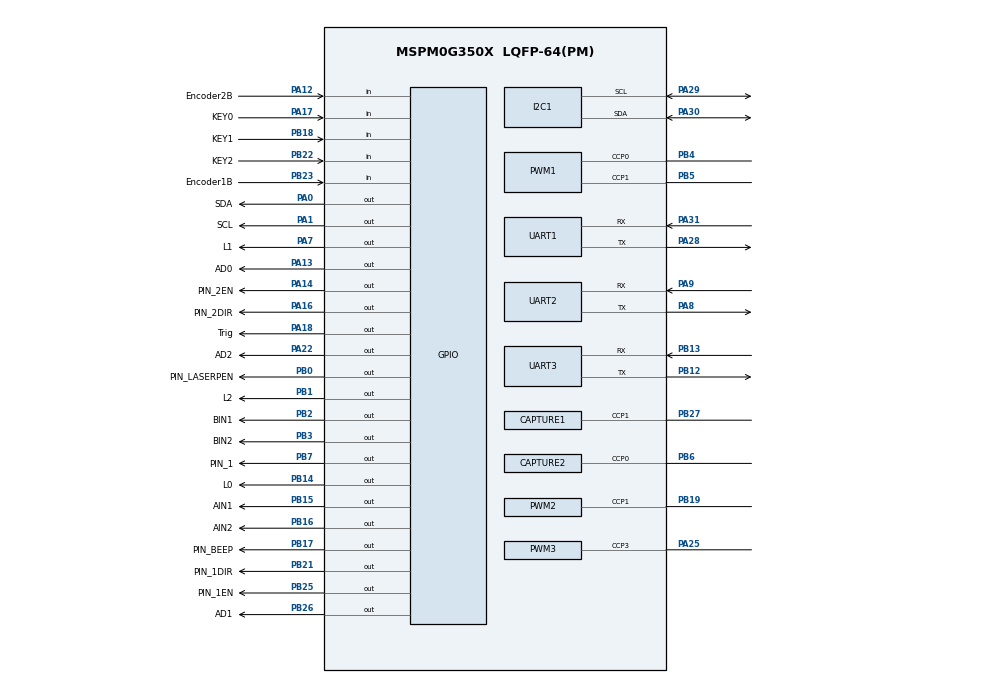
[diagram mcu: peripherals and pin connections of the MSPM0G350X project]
/**
 * @cliArgs --device "MSPM0G350X" --part "Default" --package "LQFP-64(PM)" --product "mspm0_sdk@2.05.01.01"
 * @versions {"tool":"1.24.0+4110"}
 */

/**
 * Import the modules used in this configuration.
 */
const ADC12    = scripting.addModule("/ti/driverlib/ADC12", {}, false);
const ADC121   = ADC12.addInstance();
const Board    = scripting.addModule("/ti/driverlib/Board");
const CAPTURE  = scripting.addModule("/ti/driverlib/CAPTURE", {}, false);
const CAPTURE1 = CAPTURE.addInstance();
const CAPTURE2 = CAPTURE.addInstance();
const DMA      = scripting.addModule("/ti/driverlib/DMA");
const GPIO     = scripting.addModule("/ti/driverlib/GPIO", {}, false);
const GPIO1    = GPIO.addInstance();
const GPIO2    = GPIO.addInstance();
const GPIO3    = GPIO.addInstance();
const GPIO4    = GPIO.addInstance();
const GPIO5    = GPIO.addInstance();
const GPIO6    = GPIO.addInstance();
const GPIO7    = GPIO.addInstance();
const GPIO8    = GPIO.addInstance();
const GPIO9    = GPIO.addInstance();
const GPIO10   = GPIO.addInstance();
const I2C      = scripting.addModule("/ti/driverlib/I2C", {}, false);
const I2C1     = I2C.addInstance();
const PWM      = scripting.addModule("/ti/driverlib/PWM", {}, false);
const PWM1     = PWM.addInstance();
const PWM2     = PWM.addInstance();
const PWM3     = PWM.addInstance();
const SYSCTL   = scripting.addModule("/ti/driverlib/SYSCTL");
const TIMER    = scripting.addModule("/ti/driverlib/TIMER", {}, false);
const TIMER1   = TIMER.addInstance();
const UART     = scripting.addModule("/ti/driverlib/UART", {}, false);
const UART1    = UART.addInstance();
const UART2    = UART.addInstance();
const UART3    = UART.addInstance();

/**
 * Write custom configuration values to the imported modules.
 */
ADC121.repeatMode                        = true;
ADC121.$name                             = "ADC_CHASE";
ADC121.adcMem5chansel                    = "DL_ADC12_INPUT_CHAN_5";
ADC121.powerDownMode                     = "DL_ADC12_POWER_DOWN_MODE_MANUAL";
ADC121.configureDMA                      = true;
ADC121.enabledDMATriggers                = ["DL_ADC12_DMA_MEM0_RESULT_LOADED"];
ADC121.sampCnt                           = 1;
ADC121.adcMem0chansel                    = "DL_ADC12_INPUT_CHAN_5";
ADC121.sampleTime0                       = "62.5us";
ADC121.enabledInterrupts                 = ["DL_ADC12_INTERRUPT_DMA_DONE"];
ADC121.interruptPriority                 = "1";
ADC121.sampClkDiv                        = "DL_ADC12_CLOCK_DIVIDE_8";
ADC121.DMA_CHANNEL.$name                 = "DMA_CH0";
ADC121.DMA_CHANNEL.addressMode           = "f2b";
ADC121.DMA_CHANNEL.srcLength             = "HALF_WORD";
ADC121.DMA_CHANNEL.dstLength             = "HALF_WORD";
ADC121.DMA_CHANNEL.configureTransferSize = true;
ADC121.DMA_CHANNEL.transferMode          = "FULL_CH_REPEAT_SINGLE";
ADC121.DMA_CHANNEL.transferSize          = 20;
ADC121.DMA_CHANNEL.peripheral.$assign    = "DMA_CH1";
ADC121.adcPin5Config.$name               = "ti_driverlib_gpio_GPIOPinGeneric5";

Board.genPeriphPinFile = true;
Board.genFileMod.$name = "ti_driverlib_BoardPins0";

CAPTURE1.$name                      = "Encoder1A";
CAPTURE1.timerPeriod                = "1ms";
CAPTURE1.ccIndex                    = 1;
CAPTURE1.interrupts                 = ["CC1_DN"];
CAPTURE1.peripheral.$assign         = "TIMG6";
CAPTURE1.peripheral.ccp1Pin.$assign = "PB27";
CAPTURE1.ccp1PinConfig.$name        = "ti_driverlib_gpio_GPIOPinGeneric1";

CAPTURE2.$name                              = "Encoder2A";
CAPTURE2.timerPeriod                        = "1 ms";
CAPTURE2.interrupts                         = ["CC0_DN"];
CAPTURE2.peripheral.$assign                 = "TIMG8";
CAPTURE2.peripheral.ccp0Pin.$assign         = "PB6";
CAPTURE2.ccp0PinConfig.hideOutputInversion  = scripting.forceWrite(false);
CAPTURE2.ccp0PinConfig.onlyInternalResistor = scripting.forceWrite(false);
CAPTURE2.ccp0PinConfig.passedPeripheralType = scripting.forceWrite("Digital");
CAPTURE2.ccp0PinConfig.$name                = "ti_driverlib_gpio_GPIOPinGeneric8";

GPIO1.$name                         = "MOTOR_IN";
GPIO1.associatedPins.create(4);
GPIO1.associatedPins[0].$name       = "AIN1";
GPIO1.associatedPins[0].pin.$assign = "PB15";
GPIO1.associatedPins[1].$name       = "AIN2";
GPIO1.associatedPins[1].pin.$assign = "PB16";
GPIO1.associatedPins[2].$name       = "BIN1";
GPIO1.associatedPins[2].pin.$assign = "PB2";
GPIO1.associatedPins[3].$name       = "BIN2";
GPIO1.associatedPins[3].pin.$assign = "PB3";

GPIO2.$name                         = "GPIO_Encoder";
GPIO2.associatedPins.create(2);
GPIO2.associatedPins[0].$name       = "Encoder1B";
GPIO2.associatedPins[0].direction   = "INPUT";
GPIO2.associatedPins[0].pin.$assign = "PB23";
GPIO2.associatedPins[1].$name       = "Encoder2B";
GPIO2.associatedPins[1].direction   = "INPUT";
GPIO2.associatedPins[1].pin.$assign = "PA12";

GPIO3.$name                         = "GPIO_STBY";
GPIO3.associatedPins[0].$name       = "PIN_1";
GPIO3.associatedPins[0].pin.$assign = "PB7";

GPIO4.$name                              = "GPIO_TRACE";
GPIO4.associatedPins.create(3);
GPIO4.associatedPins[0].internalResistor = "PULL_UP";
GPIO4.associatedPins[0].$name            = "AD0";
GPIO4.associatedPins[0].pin.$assign      = "PA13";
GPIO4.associatedPins[1].internalResistor = "PULL_UP";
GPIO4.associatedPins[1].$name            = "AD1";
GPIO4.associatedPins[1].pin.$assign      = "PB26";
GPIO4.associatedPins[2].internalResistor = "PULL_UP";
GPIO4.associatedPins[2].$name            = "AD2";
GPIO4.associatedPins[2].pin.$assign      = "PA22";

GPIO5.$name                              = "KEY";
GPIO5.associatedPins.create(3);
GPIO5.associatedPins[0].direction        = "INPUT";
GPIO5.associatedPins[0].polarity         = "FALL";
GPIO5.associatedPins[0].$name            = "KEY0";
GPIO5.associatedPins[0].internalResistor = "PULL_DOWN";
GPIO5.associatedPins[0].pin.$assign      = "PA17";
GPIO5.associatedPins[1].direction        = "INPUT";
GPIO5.associatedPins[1].polarity         = "FALL";
GPIO5.associatedPins[1].$name            = "KEY1";
GPIO5.associatedPins[1].internalResistor = "PULL_DOWN";
GPIO5.associatedPins[1].pin.$assign      = "PB18";
GPIO5.associatedPins[2].direction        = "INPUT";
GPIO5.associatedPins[2].polarity         = "FALL";
GPIO5.associatedPins[2].$name            = "KEY2";
GPIO5.associatedPins[2].internalResistor = "PULL_DOWN";
GPIO5.associatedPins[2].pin.$assign      = "PB22";

GPIO6.$name                              = "LED";
GPIO6.associatedPins.create(3);
GPIO6.associatedPins[0].$name            = "L0";
GPIO6.associatedPins[0].initialValue     = "SET";
GPIO6.associatedPins[0].internalResistor = "PULL_UP";
GPIO6.associatedPins[0].pin.$assign      = "PB14";
GPIO6.associatedPins[1].initialValue     = "SET";
GPIO6.associatedPins[1].$name            = "L1";
GPIO6.associatedPins[1].internalResistor = "PULL_UP";
GPIO6.associatedPins[1].pin.$assign      = "PA7";
GPIO6.associatedPins[2].initialValue     = "SET";
GPIO6.associatedPins[2].$name            = "L2";
GPIO6.associatedPins[2].internalResistor = "PULL_UP";
GPIO6.associatedPins[2].pin.$assign      = "PB1";

GPIO7.$name                         = "GPIO_OLED";
GPIO7.associatedPins.create(2);
GPIO7.associatedPins[0].$name       = "SCL";
GPIO7.associatedPins[0].pin.$assign = "PA1";
GPIO7.associatedPins[1].$name       = "SDA";
GPIO7.associatedPins[1].pin.$assign = "PA0";

GPIO8.$name                         = "GPIO_BUJIN";
GPIO8.associatedPins.create(4);
GPIO8.associatedPins[0].$name       = "PIN_1EN";
GPIO8.associatedPins[0].pin.$assign = "PB25";
GPIO8.associatedPins[1].$name       = "PIN_1DIR";
GPIO8.associatedPins[1].pin.$assign = "PB21";
GPIO8.associatedPins[2].$name       = "PIN_2EN";
GPIO8.associatedPins[2].pin.$assign = "PA14";
GPIO8.associatedPins[3].$name       = "PIN_2DIR";
GPIO8.associatedPins[3].pin.$assign = "PA16";

GPIO9.$name                              = "SR04";
GPIO9.associatedPins.create(2);
GPIO9.associatedPins[0].$name            = "Trig";
GPIO9.associatedPins[0].initialValue     = "SET";
GPIO9.associatedPins[0].pin.$assign      = "PA18";
GPIO9.associatedPins[1].direction        = "INPUT";
GPIO9.associatedPins[1].polarity         = "RISE_FALL";
GPIO9.associatedPins[1].internalResistor = "PULL_DOWN";
GPIO9.associatedPins[1].$name            = "Echo";
GPIO9.associatedPins[1].interruptEn      = true;

GPIO10.$name                              = "GPIO_ADD";
GPIO10.associatedPins.create(2);
GPIO10.associatedPins[0].$name            = "PIN_BEEP";
GPIO10.associatedPins[0].internalResistor = "PULL_UP";
GPIO10.associatedPins[0].pin.$assign      = "PB17";
GPIO10.associatedPins[1].$name            = "PIN_LASERPEN";
GPIO10.associatedPins[1].pin.$assign      = "PB0";

I2C1.$name                             = "I2C_1";
I2C1.peripheral.$assign                = "I2C1";
I2C1.peripheral.sdaPin.$assign         = "PA30";
I2C1.peripheral.sclPin.$assign         = "PA29";
I2C1.sdaPinConfig.hideOutputInversion  = scripting.forceWrite(false);
I2C1.sdaPinConfig.onlyInternalResistor = scripting.forceWrite(false);
I2C1.sdaPinConfig.passedPeripheralType = scripting.forceWrite("Digital");
I2C1.sdaPinConfig.$name                = "ti_driverlib_gpio_GPIOPinGeneric16";
I2C1.sclPinConfig.hideOutputInversion  = scripting.forceWrite(false);
I2C1.sclPinConfig.onlyInternalResistor = scripting.forceWrite(false);
I2C1.sclPinConfig.passedPeripheralType = scripting.forceWrite("Digital");
I2C1.sclPinConfig.$name                = "ti_driverlib_gpio_GPIOPinGeneric17";

PWM1.$name                              = "Motor";
PWM1.clockPrescale                      = 32;
PWM1.pwmMode                            = "EDGE_ALIGN_UP";
PWM1.timerCount                         = 100;
PWM1.peripheral.$assign                 = "TIMA1";
PWM1.peripheral.ccp0Pin.$assign         = "PB4";
PWM1.peripheral.ccp1Pin.$assign         = "PB5";
PWM1.PWM_CHANNEL_0.$name                = "ti_driverlib_pwm_PWMTimerCC2";
PWM1.PWM_CHANNEL_1.$name                = "ti_driverlib_pwm_PWMTimerCC3";
PWM1.ccp0PinConfig.direction            = scripting.forceWrite("OUTPUT");
PWM1.ccp0PinConfig.hideOutputInversion  = scripting.forceWrite(false);
PWM1.ccp0PinConfig.onlyInternalResistor = scripting.forceWrite(false);
PWM1.ccp0PinConfig.passedPeripheralType = scripting.forceWrite("Digital");
PWM1.ccp0PinConfig.$name                = "ti_driverlib_gpio_GPIOPinGeneric6";
PWM1.ccp1PinConfig.direction            = scripting.forceWrite("OUTPUT");
PWM1.ccp1PinConfig.hideOutputInversion  = scripting.forceWrite(false);
PWM1.ccp1PinConfig.onlyInternalResistor = scripting.forceWrite(false);
PWM1.ccp1PinConfig.passedPeripheralType = scripting.forceWrite("Digital");
PWM1.ccp1PinConfig.$name                = "ti_driverlib_gpio_GPIOPinGeneric7";

PWM2.ccIndex                            = [1];
PWM2.$name                              = "PWM_BUJIN_X";
PWM2.interrupts                         = ["ZERO_EVENT"];
PWM2.interruptPriority                  = "1";
PWM2.clockPrescale                      = 64;
PWM2.ccp1PinConfig.direction            = scripting.forceWrite("OUTPUT");
PWM2.ccp1PinConfig.hideOutputInversion  = scripting.forceWrite(false);
PWM2.ccp1PinConfig.onlyInternalResistor = scripting.forceWrite(false);
PWM2.ccp1PinConfig.passedPeripheralType = scripting.forceWrite("Digital");
PWM2.ccp1PinConfig.$name                = "ti_driverlib_gpio_GPIOPinGeneric13";
PWM2.peripheral.$assign                 = "TIMG7";
PWM2.peripheral.ccp1Pin.$assign         = "PB19";
PWM2.PWM_CHANNEL_1.$name                = "ti_driverlib_pwm_PWMTimerCC4";

PWM3.$name                      = "PWM_BUJIN_Y";
PWM3.ccIndex                    = [3];
PWM3.interrupts                 = ["ZERO_EVENT"];
PWM3.interruptPriority          = "1";
PWM3.clockPrescale              = 64;
PWM3.peripheral.ccp3Pin.$assign = "PA25";
PWM3.PWM_CHANNEL_3.$name        = "ti_driverlib_pwm_PWMTimerCC0";
PWM3.ccp3PinConfig.$name        = "ti_driverlib_gpio_GPIOPinGeneric4";

SYSCTL.forceDefaultClkConfig = true;

TIMER1.timerClkPrescale   = 32;
TIMER1.interrupts         = ["ZERO"];
TIMER1.timerMode          = "PERIODIC";
TIMER1.$name              = "motor_CLOCK";
TIMER1.timerPeriod        = "10 ms";
TIMER1.interruptPriority  = "1";
TIMER1.peripheral.$assign = "TIMG0";

UART1.$name                             = "UART_0";
UART1.targetBaudRate                    = 115200;
UART1.enableFIFO                        = true;
UART1.rxFifoThreshold                   = "DL_UART_RX_FIFO_LEVEL_3_4_FULL";
UART1.enabledDMARXTriggers              = "DL_UART_DMA_INTERRUPT_RX";
UART1.enabledInterrupts                 = ["DMA_DONE_RX","RX_TIMEOUT_ERROR"];
UART1.peripheral.$assign                = "UART0";
UART1.peripheral.rxPin.$assign          = "PA31";
UART1.peripheral.txPin.$assign          = "PA28";
UART1.txPinConfig.$name                 = "ti_driverlib_gpio_GPIOPinGeneric2";
UART1.rxPinConfig.$name                 = "ti_driverlib_gpio_GPIOPinGeneric3";
UART1.DMA_CHANNEL_RX.addressMode        = "f2b";
UART1.DMA_CHANNEL_RX.srcLength          = "BYTE";
UART1.DMA_CHANNEL_RX.dstLength          = "BYTE";
UART1.DMA_CHANNEL_RX.transferMode       = "FULL_CH_REPEAT_SINGLE";
UART1.DMA_CHANNEL_RX.$name              = "DMA_MAXCI";
UART1.DMA_CHANNEL_RX.peripheral.$assign = "DMA_CH2";

UART2.$name                    = "UART_1";
UART2.enableFIFO               = true;
UART2.rxFifoThreshold          = "DL_UART_RX_FIFO_LEVEL_3_4_FULL";
UART2.enabledInterrupts        = ["RX"];
UART2.peripheral.$assign       = "UART1";
UART2.peripheral.rxPin.$assign = "PA9";
UART2.peripheral.txPin.$assign = "PA8";
UART2.txPinConfig.$name        = "ti_driverlib_gpio_GPIOPinGeneric10";
UART2.rxPinConfig.$name        = "ti_driverlib_gpio_GPIOPinGeneric11";

UART3.$name                             = "UART_3";
UART3.targetBaudRate                    = 230400;
UART3.rxFifoThreshold                   = "DL_UART_RX_FIFO_LEVEL_3_4_FULL";
UART3.enabledDMARXTriggers              = "DL_UART_DMA_INTERRUPT_RX";
UART3.enabledInterrupts                 = ["DMA_DONE_RX","RX_TIMEOUT_ERROR"];
UART3.enableFIFO                        = true;
UART3.peripheral.$assign                = "UART3";
UART3.peripheral.rxPin.$assign          = "PB13";
UART3.peripheral.txPin.$assign          = "PB12";
UART3.txPinConfig.direction             = scripting.forceWrite("OUTPUT");
UART3.txPinConfig.hideOutputInversion   = scripting.forceWrite(false);
UART3.txPinConfig.onlyInternalResistor  = scripting.forceWrite(false);
UART3.txPinConfig.passedPeripheralType  = scripting.forceWrite("Digital");
UART3.txPinConfig.$name                 = "ti_driverlib_gpio_GPIOPinGeneric0";
UART3.rxPinConfig.hideOutputInversion   = scripting.forceWrite(false);
UART3.rxPinConfig.onlyInternalResistor  = scripting.forceWrite(false);
UART3.rxPinConfig.passedPeripheralType  = scripting.forceWrite("Digital");
UART3.rxPinConfig.$name                 = "ti_driverlib_gpio_GPIOPinGeneric15";
UART3.DMA_CHANNEL_RX.dstLength          = "BYTE";
UART3.DMA_CHANNEL_RX.addressMode        = "f2b";
UART3.DMA_CHANNEL_RX.srcLength          = "BYTE";
UART3.DMA_CHANNEL_RX.transferMode       = "FULL_CH_REPEAT_SINGLE";
UART3.DMA_CHANNEL_RX.$name              = "DMA_STP";
UART3.DMA_CHANNEL_RX.peripheral.$assign = "DMA_CH0";

/**
 * Pinmux solution for unlocked pins/peripherals. This ensures that minor changes to the automatic solver in a future
 * version of the tool will not impact the pinmux you originally saw.  These lines can be completely deleted in order to
 * re-solve from scratch.
 */
ADC121.peripheral.$suggestSolution           = "ADC0";
ADC121.peripheral.adcPin5.$suggestSolution   = "PB24";
Board.peripheral.$suggestSolution            = "DEBUGSS";
Board.peripheral.swclkPin.$suggestSolution   = "PA20";
Board.peripheral.swdioPin.$suggestSolution   = "PA19";
GPIO9.associatedPins[1].pin.$suggestSolution = "PA15";
PWM3.peripheral.$suggestSolution             = "TIMA0";
SYSCTL.peripheral.$suggestSolution           = "SYSCTL";
